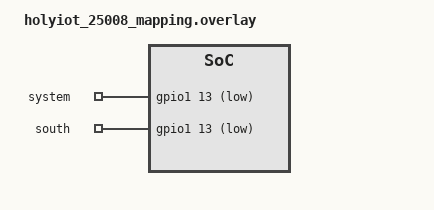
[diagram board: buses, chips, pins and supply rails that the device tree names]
/ {
    gamepad-buttons {
        compatible = "gpio-keys";
        /* same as south */
        system { gpios = <&gpio1 13 (GPIO_PULL_UP | GPIO_ACTIVE_LOW)>; };
        south { gpios = <&gpio1 13 (GPIO_PULL_UP | GPIO_ACTIVE_LOW)>; };
    };
};
